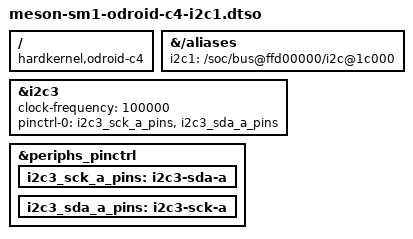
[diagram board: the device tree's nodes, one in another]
/dts-v1/;
/plugin/;

/ {
	compatible = "hardkernel,odroid-c4", "amlogic,sm1";

	fragment@0 {
		target-path = "/aliases";
		__overlay__ {
			i2c1 = "/soc/bus@ffd00000/i2c@1c000";
		};
	};

	fragment@1 {
		target = <&i2c3>;
		__overlay__ {
			status = "okay";
			clock-frequency = <100000>;
			pinctrl-0 = <&i2c3_sck_a_pins &i2c3_sda_a_pins>;
			pinctrl-names = "default";
		};
	};

	fragment@2 {
		target = <&periphs_pinctrl>;
		__overlay__ {
			i2c3_sck_a_pins: i2c3-sda-a { };
			i2c3_sda_a_pins: i2c3-sck-a { };
		};
	};

};
